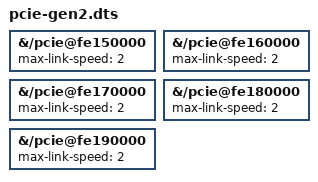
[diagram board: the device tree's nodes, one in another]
/dts-v1/;
/plugin/;

/* Force Gen2 (Standard for PCIe 2.1) to ensure enough DMA bandwidth for 2.5G NICs */

&{/pcie@fe150000} {
    max-link-speed = <2>;
};

&{/pcie@fe160000} {
    max-link-speed = <2>;
};

&{/pcie@fe170000} {
    max-link-speed = <2>;
};

&{/pcie@fe180000} {
    max-link-speed = <2>;
};

&{/pcie@fe190000} {
    max-link-speed = <2>;
};
